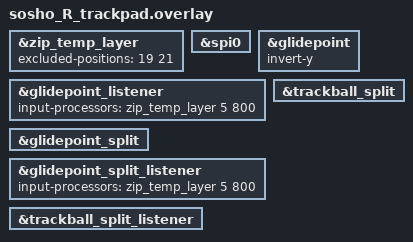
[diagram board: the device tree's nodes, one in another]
#include "sosho_R.dtsi"

&zip_temp_layer {
    // JとLを押してもマウスレイヤーを維持する
    excluded-positions = <19 21>;
};

&spi0 { status = "okay"; };
&glidepoint {
    status = "okay";
    invert-y;
};
&glidepoint_listener {
    status = "okay";
    // 最後のトラックパッド操作から0.8秒間マウスレイヤーを有効にする
    input-processors = <&zip_temp_layer 5 800>;
};

&glidepoint_split { status = "okay"; };
&glidepoint_split_listener {
    status = "okay";
    // 左側トラックパッドにもオートマウスレイヤーを適用する
    input-processors = <&zip_temp_layer 5 800>;
};

&trackball_split { status = "okay"; };
&trackball_split_listener { status = "okay"; };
